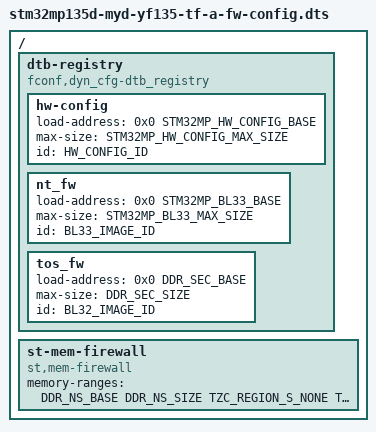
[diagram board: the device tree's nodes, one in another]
// SPDX-License-Identifier: (GPL-2.0-or-later OR BSD-3-Clause)
// Copyright 2026 Deadband Inc.
/*
 * TF-A FW_CONFIG for DBL MYD-YF135-256N-256D
 *
 * Describes load addresses and sizes for BL32 (OP-TEE) and BL33 (U-Boot).
 * Memory layout must match Linux DTS reserved-memory and OP-TEE build config:
 *   BL32 (OP-TEE) -> 0xce000000, 32 MB  (CFG_TZDRAM_START)
 *   BL33 (U-Boot) -> STM32MP_BL33_BASE  (defined by TF-A platform)
 *
 * Taken from basiccode-STM32MP135_Dev_Board_Buildroot (identical memory layout).
 */

#include <common/tbbr/tbbr_img_def.h>
#include <dt-bindings/soc/stm32mp13-tzc400.h>
#include <platform_def.h>

#define DDR_SIZE	0x10000000 /* 256 MB */
#define DDR_NS_BASE	0xc0000000
#define DDR_NS_SIZE	0x0e000000
#define DDR_SEC_SIZE	0x02000000
#define DDR_SEC_BASE	0xce000000

/dts-v1/;

/ {
	dtb-registry {
		compatible = "fconf,dyn_cfg-dtb_registry";

		hw-config {
			load-address = <0x0 STM32MP_HW_CONFIG_BASE>;
			max-size = <STM32MP_HW_CONFIG_MAX_SIZE>;
			id = <HW_CONFIG_ID>;
		};

		nt_fw {
			load-address = <0x0 STM32MP_BL33_BASE>;
			max-size = <STM32MP_BL33_MAX_SIZE>;
			id = <BL33_IMAGE_ID>;
		};

		tos_fw {
			load-address = <0x0 DDR_SEC_BASE>;
			max-size = <DDR_SEC_SIZE>;
			id = <BL32_IMAGE_ID>;
		};
	};

	st-mem-firewall {
		compatible = "st,mem-firewall";
		memory-ranges = <
			DDR_NS_BASE DDR_NS_SIZE TZC_REGION_S_NONE TZC_REGION_NSEC_ALL_ACCESS_RDWR
			DDR_SEC_BASE DDR_SEC_SIZE TZC_REGION_S_RDWR 0>;
	};
};
